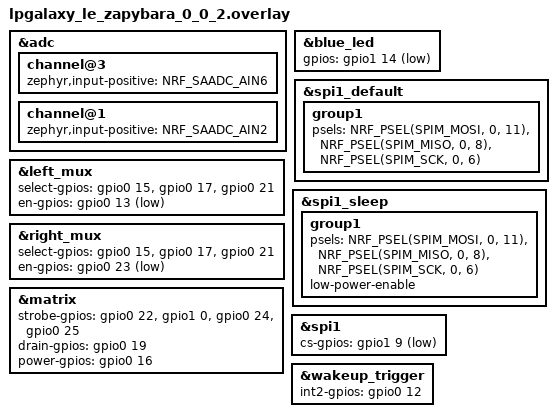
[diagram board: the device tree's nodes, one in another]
/*
 * Copyright (c) 2020 The ZMK Contributors
 *
 * SPDX-License-Identifier: MIT
 */

#include <zephyr/dt-bindings/dt-util.h>
#include <zephyr/dt-bindings/adc/adc.h>
#include <zephyr/dt-bindings/gpio/nordic-nrf-gpio.h>

#include <freq.h>

&adc {
    // Battery Sensing
    channel@3 {
        zephyr,input-positive = <NRF_SAADC_AIN6>; /* P0.30 */
    };

    // EC Read
    channel@1 {
        zephyr,input-positive = <NRF_SAADC_AIN2>; /* P0.30 */
    };
};

&left_mux {
    select-gpios
        = <&gpio0 15 GPIO_ACTIVE_HIGH>
        , <&gpio0 17 GPIO_ACTIVE_HIGH>
        , <&gpio0 21 GPIO_ACTIVE_HIGH>
        ;
    en-gpios = <&gpio0 13 GPIO_ACTIVE_LOW>;
};

&right_mux {
    select-gpios
        = <&gpio0 15 GPIO_ACTIVE_HIGH>
        , <&gpio0 17 GPIO_ACTIVE_HIGH>
        , <&gpio0 21 GPIO_ACTIVE_HIGH>
        ;
    en-gpios = <&gpio0 23 GPIO_ACTIVE_LOW>;
};

&blue_led {
    gpios = <&gpio1 14 GPIO_ACTIVE_LOW>;
};

&matrix {
    strobe-gpios
        = <&gpio0 22 (GPIO_ACTIVE_HIGH| NRF_GPIO_DRIVE_H0H1)>
        , <&gpio1  0 (GPIO_ACTIVE_HIGH| NRF_GPIO_DRIVE_H0H1)>
        , <&gpio0 24 (GPIO_ACTIVE_HIGH| NRF_GPIO_DRIVE_H0H1)>
        , <&gpio0 25 (GPIO_ACTIVE_HIGH| NRF_GPIO_DRIVE_H0H1)>
        ;

    drain-gpios = <&gpio0 19 (GPIO_ACTIVE_HIGH | NRF_GPIO_DRIVE_H0H1)>;
    power-gpios = <&gpio0 16 (GPIO_ACTIVE_HIGH | NRF_GPIO_DRIVE_H0H1)>;
};

&spi1_default {
    group1 {
        psels = <NRF_PSEL(SPIM_MOSI, 0, 11)>,
            <NRF_PSEL(SPIM_MISO, 0, 8)>,
            <NRF_PSEL(SPIM_SCK, 0, 6)>;
    };
};

&spi1_sleep {
    group1 {
        psels = <NRF_PSEL(SPIM_MOSI, 0, 11)>,
            <NRF_PSEL(SPIM_MISO, 0, 8)>,
            <NRF_PSEL(SPIM_SCK, 0, 6)>;
        low-power-enable;
    };
};

&spi1 {
    cs-gpios = <&gpio1 9 GPIO_ACTIVE_LOW>;
};

&wakeup_trigger {
    int2-gpios = <&gpio0 12 (GPIO_ACTIVE_HIGH)>;
};

